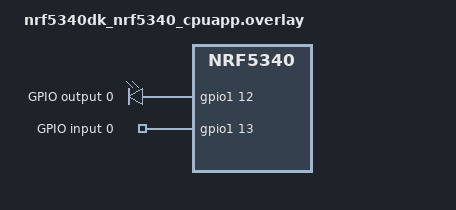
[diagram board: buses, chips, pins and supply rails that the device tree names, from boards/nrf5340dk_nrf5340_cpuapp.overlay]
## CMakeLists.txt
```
#
# Copyright (c) 2024 Nordic Semiconductor ASA
#
# SPDX-License-Identifier: LicenseRef-Nordic-5-Clause
#

cmake_minimum_required(VERSION 3.20.0)

find_package(Zephyr REQUIRED HINTS $ENV{ZEPHYR_BASE})
zephyr_include_directories(include)

project(gpio)

target_sources(app PRIVATE ./../common/main.c)
target_sources(app PRIVATE src/driver_test.c)
```

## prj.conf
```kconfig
CONFIG_GPIO=y
CONFIG_CONSOLE=n
CONFIG_UART_CONSOLE=n
CONFIG_SERIAL=n
CONFIG_BOOT_BANNER=n
CONFIG_NCS_BOOT_BANNER=n

CONFIG_ASSERT=y
```

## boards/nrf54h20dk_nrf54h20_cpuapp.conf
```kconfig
# Enable runtime power management for peripheral
CONFIG_PM_DEVICE=y
CONFIG_PM_DEVICE_RUNTIME=y

CONFIG_PM=y
CONFIG_POWEROFF=y
CONFIG_SOC_NRF54H20_CPURAD_ENABLE=y
```

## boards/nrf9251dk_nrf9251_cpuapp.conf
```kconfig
# Enable runtime power management for peripheral
CONFIG_PM_DEVICE=y
CONFIG_PM_DEVICE_RUNTIME=y

CONFIG_PM=y
CONFIG_POWEROFF=y
```

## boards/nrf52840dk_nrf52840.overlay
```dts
/ {
	aliases {
		led = &led0;
		out0 = &output0;
		in0 = &input0;
	};
	outputs {
		compatible = "gpio-leds";

		output0: output_0 {
			gpios = <&gpio1 12 GPIO_ACTIVE_HIGH>;
			label = "GPIO output 0";
		};
	};

	inputs {
		compatible = "gpio-keys";

		input0: input_0 {
			gpios = <&gpio1 13 (GPIO_ACTIVE_HIGH)>;
			label = "GPIO input 0";
		};
	};
};

&gpiote {
	status = "okay";
	owned-channels = <0>;
};
```

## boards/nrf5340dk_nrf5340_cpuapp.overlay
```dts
/ {
	aliases {
		led = &led0;
		out0 = &output0;
		in0 = &input0;
	};

	outputs {
		compatible = "gpio-leds";

		output0: output_0 {
			gpios = <&gpio1 12 GPIO_ACTIVE_HIGH>;
			label = "GPIO output 0";
		};
	};

	inputs {
		compatible = "gpio-keys";

		input0: input_0 {
			gpios = <&gpio1 13 GPIO_ACTIVE_HIGH>;
			label = "GPIO input 0";
		};
	};
};

&gpiote1 {
	status = "okay";
	owned-channels = <0>;
};

&vregmain {
	regulator-initial-mode = <NRF5X_REG_MODE_LDO>;
};
```

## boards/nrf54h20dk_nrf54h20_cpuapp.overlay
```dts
/ {
	aliases {
		led = &led0;
		/delete-property/ led1;
		out0 = &output0;
		in0 = &input0;
	};

	outputs {
		compatible = "gpio-leds";

		output0: output_0 {
			gpios = <&gpio0 0 GPIO_ACTIVE_HIGH>;
			label = "GPIO output 0";
		};
	};

	inputs {
		compatible = "gpio-keys";

		input0: input_0 {
			gpios = <&gpio0 1 GPIO_ACTIVE_HIGH>;
			label = "GPIO input 0";
		};
	};
};

/delete-node/ &led1;

&gpiote130 {
	status = "okay";
	owned-channels = <0>;
};
```

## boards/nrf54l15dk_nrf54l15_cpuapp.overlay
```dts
/ {
	aliases {
		led = &button3;
		/delete-property/ sw1;
		/delete-property/ sw2;
		out0 = &output0;
		in0 = &input0;
	};

	outputs {
		compatible = "gpio-leds";

		output0: output_0 {
			gpios = <&gpio1 8 GPIO_ACTIVE_HIGH>;
			label = "GPIO output 0";
		};
	};

	inputs {
		compatible = "gpio-keys";

		input0: input_0 {
			gpios = <&gpio1 9 GPIO_ACTIVE_HIGH>;
			label = "GPIO input 0";
		};
	};
};

/delete-node/ &button1;
/delete-node/ &button2;
```

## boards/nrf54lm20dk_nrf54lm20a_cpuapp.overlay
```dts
/ {
	aliases {
		led = &led0;
		/delete-property/ led1;
		out0 = &output0;
		in0 = &input0;
	};

	outputs {
		compatible = "gpio-leds";

		output0: output_0 {
			gpios = <&gpio1 30 GPIO_ACTIVE_HIGH>;
			label = "GPIO output 0";
		};
	};

	inputs {
		compatible = "gpio-keys";

		input0: input_0 {
			gpios = <&gpio1 31 GPIO_ACTIVE_HIGH>;
			label = "GPIO input 0";
		};
	};
};

/delete-node/ &led1;

&gpiote20 {
	status = "okay";
	owned-channels = <0>;
};
```

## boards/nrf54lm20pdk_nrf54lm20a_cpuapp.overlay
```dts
/ {
	aliases {
		led = &led0;
		/delete-property/ led1;
		out0 = &output0;
		in0 = &input0;
	};
	outputs {
		compatible = "gpio-leds";

		output0: output_0 {
			gpios = <&gpio1 30 GPIO_ACTIVE_HIGH>;
			label = "GPIO output 0";
		};
	};

	inputs {
		compatible = "gpio-keys";

		input0: input_0 {
			gpios = <&gpio1 31 (GPIO_ACTIVE_HIGH)>;
			label = "GPIO input 0";
		};
	};
};

/delete-node/ &led1;

&gpiote20 {
	status = "okay";
	owned-channels = <0>;
};
```

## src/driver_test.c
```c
/*
 * Copyright (c) 2024 Nordic Semiconductor ASA
 *
 * SPDX-License-Identifier: LicenseRef-Nordic-5-Clause
 */

#include <zephyr/drivers/gpio.h>
#include <zephyr/kernel.h>
#include <zephyr/irq.h>

#define OUTPUT_NODE DT_ALIAS(out0)
#define INPUT_NODE  DT_ALIAS(in0)

static const struct gpio_dt_spec output = GPIO_DT_SPEC_GET(OUTPUT_NODE, gpios);
static const struct gpio_dt_spec input = GPIO_DT_SPEC_GET(INPUT_NODE, gpios);
volatile int counter;

static struct gpio_callback input_active_cb_data;

void input_active(const struct device *dev, struct gpio_callback *cb, uint32_t pins)
{
	counter++;
}

void thread_definition(void)
{
	int rc;
	unsigned int key;

	rc = gpio_is_ready_dt(&input);
	__ASSERT_NO_MSG(rc);

	rc = gpio_is_ready_dt(&output);
	__ASSERT_NO_MSG(rc);

	rc = gpio_pin_configure_dt(&input, GPIO_INPUT);
	__ASSERT_NO_MSG(rc == 0);

	rc = gpio_pin_configure_dt(&output, GPIO_OUTPUT);
	__ASSERT_NO_MSG(rc == 0);

	rc = gpio_pin_interrupt_configure_dt(&input, GPIO_INT_LEVEL_ACTIVE);
	__ASSERT_NO_MSG(rc == 0);

	gpio_init_callback(&input_active_cb_data, input_active, BIT(input.pin));
	gpio_add_callback_dt(&input, &input_active_cb_data);

	while (1) {
		counter = 0;
		key = irq_lock();
		rc = gpio_pin_set_dt(&output, 0);
		rc = gpio_pin_set_dt(&output, 1);
		rc = gpio_pin_set_dt(&output, 0);
		irq_unlock(key);
		k_usleep(1);
		__ASSERT_NO_MSG(counter == 1);

		k_msleep(10);
	}
}
```
